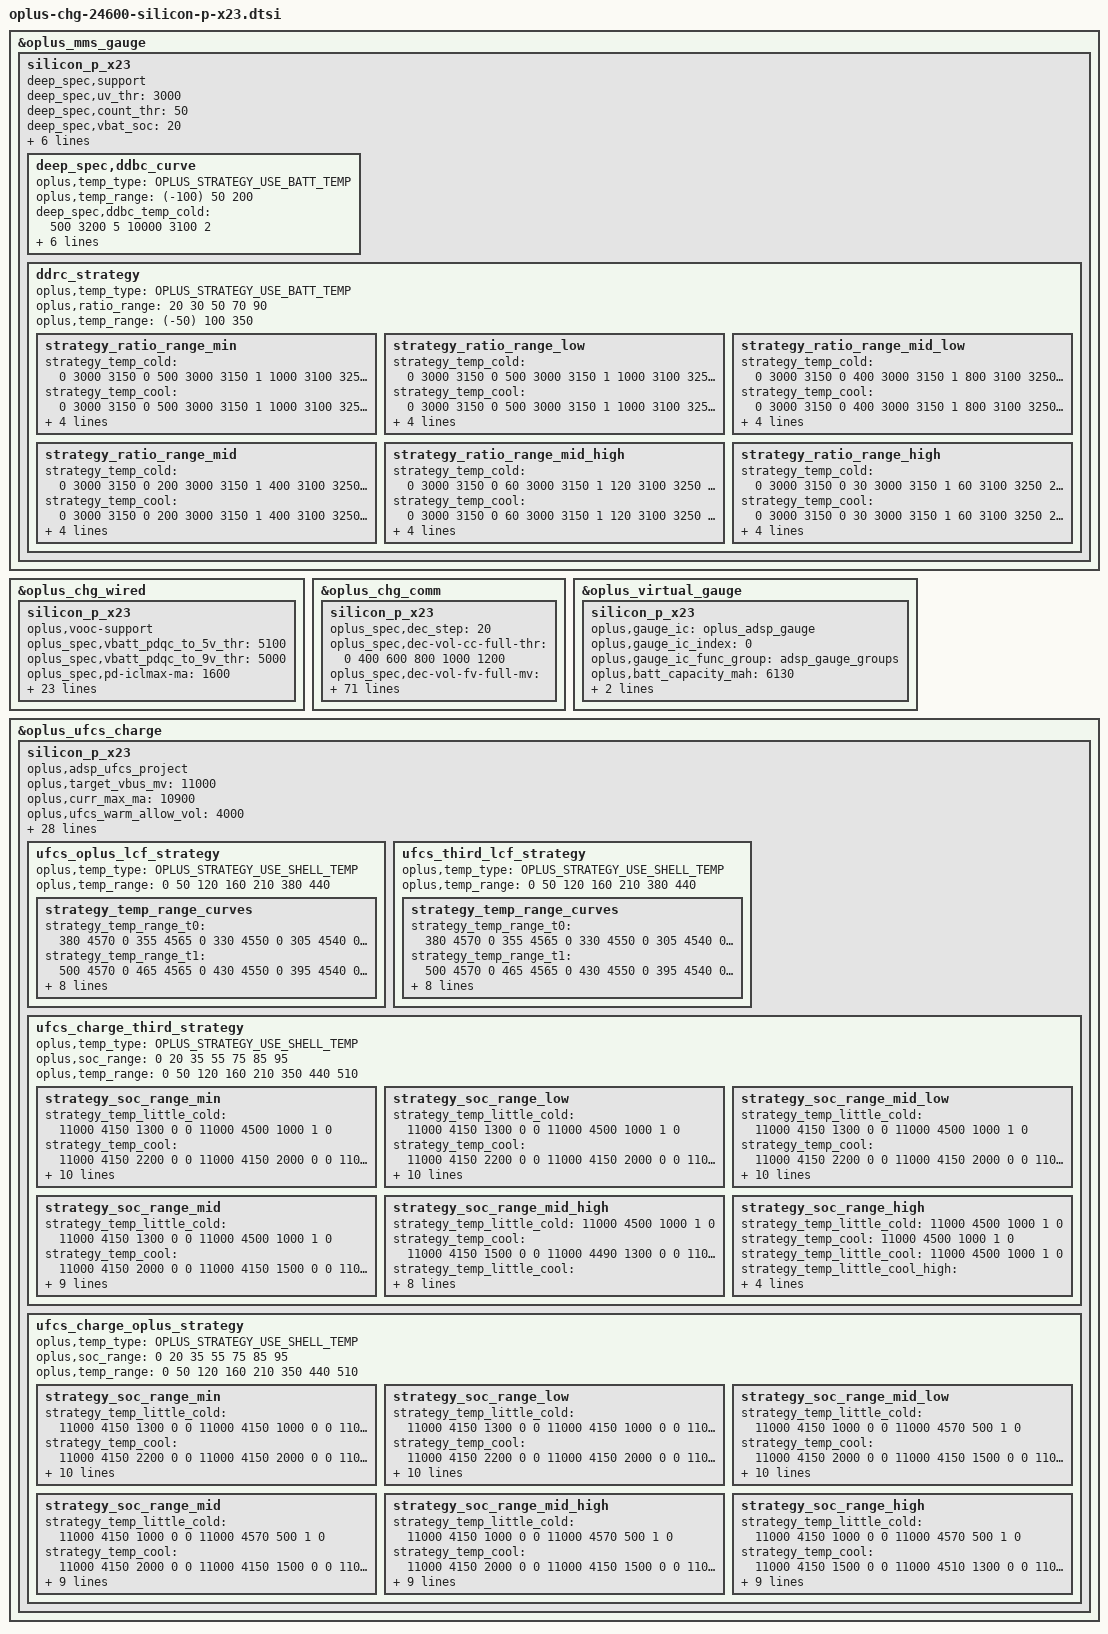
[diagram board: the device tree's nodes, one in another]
//ifdef OPLUS_FEATURE_CHG_BASIC

&oplus_mms_gauge {
	silicon_p_x23 {
		deep_spec,support;
		deep_spec,uv_thr = <3000>;
		deep_spec,count_thr = <50>;
		deep_spec,vbat_soc = <20>;
		deep_spec,count_step = <0 10 0
					350 12 1
					450 15 2
					530 20 3>;

		deep_spec,term_coeff = <3000 220 0
					3100 330 2
					3150 380 3
					3250 490 5
					3300 550 7
					3370 600 8
					3400 600 8>;
		deep_spec,ddrc_strategy_name = "ddrc_curve";
		deep_spec,volt_step = <20>;
		deep_spec,ddbc_curve {
			oplus,temp_type = <OPLUS_STRATEGY_USE_BATT_TEMP>;
			oplus,temp_range = <(-100) 50 200>;
			deep_spec,ddbc_temp_cold = <500 3200 5
						   10000 3100 2>;
			deep_spec,ddbc_temp_cool = <500 3300 5
						   10000 3200 2>;
			deep_spec,ddbc_temp_normal = <500 3400 5
						   10000 3350 2>;
			deep_spec,ddbc_temp_warm = <500 3400 5
						   10000 3350 2>;
		};
		ddrc_strategy {
			oplus,temp_type = <OPLUS_STRATEGY_USE_BATT_TEMP>;
			oplus,ratio_range = <20 30 50 70 90>;
			oplus,temp_range = <(-50) 100 350>;
			strategy_ratio_range_min {
				strategy_temp_cold =	<0 3000 3150 0
							500 3000 3150 1
							1000 3100 3250 2>;
				strategy_temp_cool =	<0 3000 3150 0
							500 3000 3150 1
							1000 3100 3250 2>;
				strategy_temp_normal =	<0 3000 3150 0
							500 3100 3250 1
							1000 3200 3300 2>;
				strategy_temp_warm =	<0 3000 3150 0
							500 3100 3250 1
							1000 3200 3300 2>;
			};
			strategy_ratio_range_low {
				strategy_temp_cold =	<0 3000 3150 0
							500 3000 3150 1
							1000 3100 3250 2>;
				strategy_temp_cool =	<0 3000 3150 0
							500 3000 3150 1
							1000 3100 3250 2>;
				strategy_temp_normal =	<0 3000 3150 0
							500 3100 3250 1
							1000 3200 3300 2>;
				strategy_temp_warm =	<0 3000 3150 0
							500 3100 3250 1
							1000 3200 3300 2>;
			};
			strategy_ratio_range_mid_low {
				strategy_temp_cold =	<0 3000 3150 0
							400 3000 3150 1
							800 3100 3250 2>;
				strategy_temp_cool =	<0 3000 3150 0
							400 3000 3150 1
							800 3100 3250 2>;
				strategy_temp_normal =	<0 3000 3150 0
							400 3100 3250 1
							800 3200 3300 2>;
				strategy_temp_warm =	<0 3000 3150 0
							400 3100 3250 1
							800 3200 3300 2>;
			};
			strategy_ratio_range_mid {
				strategy_temp_cold =	<0 3000 3150 0
							200 3000 3150 1
							400 3100 3250 2
							1000 3100 3250 3>;
				strategy_temp_cool =	<0 3000 3150 0
							200 3000 3150 1
							400 3100 3250 2
							1000 3200 3300 3>;
				strategy_temp_normal =	<0 3000 3150 0
							200 3100 3250 1
							400 3200 3300 2
							1000 3300 3370 3>;
				strategy_temp_warm =	<0 3000 3150 0
							200 3100 3250 1
							400 3200 3300 2
							1000 3300 3370 3>;
			};
			strategy_ratio_range_mid_high {
				strategy_temp_cold =	<0 3000 3150 0
							60 3000 3150 1
							120 3100 3250 2
							220 3100 3250 3
							1000 3200 3300 4>;
				strategy_temp_cool =	<0 3000 3150 0
							60 3000 3150 1
							120 3100 3250 2
							220 3200 3300 3
							1000 3200 3300 4>;
				strategy_temp_normal =	<0 3000 3150 0
							60 3100 3250 1
							120 3200 3300 2
							220 3300 3370 3
							1000 3350 3400 4>;
				strategy_temp_warm =	<0 3000 3150 0
							60 3100 3250 1
							120 3200 3300 2
							220 3300 3370 3
							800 3350 3400 4>;
			};
			strategy_ratio_range_high {
				strategy_temp_cold =	<0 3000 3150 0
							30 3000 3150 1
							60 3100 3250 2
							110 3200 3300 3
							160 3200 3300 4>;
				strategy_temp_cool =	<0 3000 3150 0
							30 3000 3150 1
							60 3100 3250 2
							110 3200 3300 3
							160 3200 3300 4>;
				strategy_temp_normal =	<0 3000 3150 0
							30 3100 3250 1
							60 3200 3300 2
							110 3300 3370 3
							160 3350 3400 4>;
				strategy_temp_warm =	<0 3000 3150 0
							30 3100 3250 1
							60 3200 3300 2
							110 3300 3370 3
							160 3350 3400 4>;
			};
		};
	};
};


&oplus_chg_wired {
	silicon_p_x23 {
		oplus,vooc-support;

		oplus_spec,vbatt_pdqc_to_5v_thr = <5100>;
		oplus_spec,vbatt_pdqc_to_9v_thr = <5000>;
		oplus_spec,pd-iclmax-ma = <1600>;
		oplus_spec,qc-iclmax-ma = <1600>;
		oplus_spec,non-standard-ibatmax-ma = <500>;
		oplus_spec,input-power-mw = <
			2500		/* OPLUS_WIRED_CHG_MODE_UNKNOWN */
			2500		/* OPLUS_WIRED_CHG_MODE_SDP */
			7500		/* OPLUS_WIRED_CHG_MODE_CDP */
			10000		/* OPLUS_WIRED_CHG_MODE_DCP */
			15000		/* OPLUS_WIRED_CHG_MODE_VOOC */
			14400		/* OPLUS_WIRED_CHG_MODE_QC */
			14400		/* OPLUS_WIRED_CHG_MODE_PD */
		>;
		oplus_spec,led_on-fccmax-ma = <0 788  1364 1760 1760 1760 1760 500 0>;
		oplus_spec,fccmax-ma-lv = <
			0 818 1100 1100 1100 1100 1100 1100  0	/* OPLUS_WIRED_CHG_MODE_UNKNOWN */
			0 300  300  300  300  300  300  300  0	/* OPLUS_WIRED_CHG_MODE_SDP */
			0 788  800  800  800  800  800  800  0	/* OPLUS_WIRED_CHG_MODE_CDP */
			0 788  1100 1100 1100 1100 1100 1100 0	/* OPLUS_WIRED_CHG_MODE_DCP */
			0 788  1314 1650 1650 1650 1650 1577 0	/* OPLUS_WIRED_CHG_MODE_VOOC */
			0 788  1314 1760 1760 1760 1760 1577 0	/* OPLUS_WIRED_CHG_MODE_QC */
			0 788  1314 1760 1760 1760 1760 1577 0	/* OPLUS_WIRED_CHG_MODE_PD */
		>;
		oplus_spec,fccmax-ma-hv = <
			0 263  526  1100 1100 1100 1100 1100  0	/* OPLUS_WIRED_CHG_MODE_UNKNOWN */
			0 263  300  300  300  300  300  300   0	/* OPLUS_WIRED_CHG_MODE_SDP */
			0 263  526  800  800  800  800  800   0	/* OPLUS_WIRED_CHG_MODE_CDP */
			0 263  526  1100 1100 1100 1100 1100  0	/* OPLUS_WIRED_CHG_MODE_DCP */
			0 263  526  1314 1314 1650 1650 1577  0	/* OPLUS_WIRED_CHG_MODE_VOOC */
			0 263  526  1314 1314 1760 1760 1577  0	/* OPLUS_WIRED_CHG_MODE_QC */
			0 263  526  1314 1314 1760 1760 1577  0	/* OPLUS_WIRED_CHG_MODE_PD */
		>;

		oplus_spec,cool_down_pdqc_vol_mv = <9000 9000 9000>;
		oplus_spec,cool_down_pdqc_curr_ma = <1200 1600 1600>;
		oplus_spec,cool_down_vooc_curr_ma = <1200 1500 2000 2500 3000 3000>;
		oplus_spec,cool_down_normal_curr_ma = <1200 1500 2000>;

		oplus_spec,vbus_ov_thr_mv = <11000 11000>;
		oplus_spec,vbus_uv_thr_mv = <4300 4300>;

		/* first data is strategy used temp type */
		oplus,vooc_strategy_name = "cgcl";
		oplus,vooc_strategy_data = <OPLUS_STRATEGY_USE_BATT_TEMP
					    0   350 3000 1 0
					    330 370 3000 2 0
					    350 440 2200 2 1>;
	};
};
&oplus_chg_comm {
	silicon_p_x23 {
		oplus_spec,dec_step = <20>;
		oplus_spec,dec-vol-cc-full-thr = <0 400 600 800 1000 1200>;
		oplus_spec,dec-vol-fv-full-mv = <0 20 20 40 40 40>;
		oplus_spec,batt-them-thr = <(-100) 0 50 120 160 350 450 530>;
		oplus_spec,iterm-ma = <156>;
		oplus_spec,fv-mv = <4500 4500 4500 4500 4500 4500 4485 4130 4130>;
		oplus_spec,sw-fv-mv = <4450 4450 4450 4450 4450 4450 4435 4080 4080>;
		oplus_spec,hw-fv-inc-mv = <0 18 18 18 18 18 18 18 0>;
		oplus_spec,sw-over-fv-mv = <4510 4510 4510 4510 4510 4510 4495 4140 4140>;
		oplus_spec,sw-over-fv-dec-mv = <8>;
		oplus_spec,non-standard-sw-fv-mv = <3930>;
		oplus_spec,non-standard-fv-mv = <3980>;
		oplus_spec,non-standard-hw-fv-inc-mv = <18>;
		oplus_spec,non-standard-sw-over-fv-mv = <3990>;
		oplus_spec,non-standard-vbatdet-mv = <3680>;
		oplus_spec,wired-vbatdet-mv = <0 4200 4300 4400 4400 4400 4385 4030 0>;
		oplus_spec,fcc-gear-thr-mv = <4180>;
		oplus_spec,fcc-gear-shake-mv = <400 400 400 300 300 180 180 180 180>;
		oplus_spec,vbatt-ov-thr-mv = <4600>;

		oplus_spec,full_pre_ffc_judge;
		oplus_spec,full-pre-ffc-mv = <4495>;
		oplus_spec,ffc-temp-thr = <120 200 350 440>;
		oplus_spec,wired-ffc-step-max = <2>;
		oplus_spec,wired-ffc-fv-mv = <4590 4590>;

		oplus_spec,wired-ffc-fv-cutoff-mv = <4545 4515 4500
						     4515 4505 4490>;

		oplus_spec,removed_bat_decidegc = <390>;

		oplus_spec,wired-ffc-fcc-ma = <550 550 550
					       350 350 350>;
		oplus_spec,wired-ffc-fcc-cutoff-ma = <400 400 400
						      200 200 200>;

		oplus_spec,drop_soc_2_temp_ladder = <(-50) 0 0 0 0 0 0 0 0 0>;
		oplus_spec,volt_diff_ladder_of_drop_soc_2 = <20 50 0 0 0 0 0 0 0 0>;
		oplus_spec,keep_soc_2_temp_ladder = <(-200) (-50) 0 0 0 0 0 0 0 0>;
		oplus_spec,volt_diff_ladder_of_keep_soc_2 = <10 20 30 0 0 0 0 0 0 0>;
		oplus_spec,back_rm_of_drop_soc_2 = <60>;
		oplus_spec,back_rm_of_drop_soc_1 = <60>;
		oplus_spec,load_current_of_drop_soc_2 = <500>;
		oplus_spec,load_current_of_drop_soc_1 = <1000>;
		oplus_spec,current_limit_of_drop_soc_2 = <350>;
		oplus_spec,volt_of_fast_drop_soc_1 = <3050>;
		oplus_spec,support_uisoc_low_battery_control;

		/* 2s battery */
		oplus_spec,wired-aging-ffc-version = <AGING_FFC_V1>;
		oplus_spec,wired-aging-ffc-offset-mv = <15 30
							10 20>;
		oplus_spec,wired-aging-ffc-cycle-thr = <500 1000>;

		oplus_spec,vbat_uv_thr_mv = <3000>;
		oplus_spec,vbat_charging_uv_thr_mv = <2900>;

		/*If use subboard NTC as battery temp, config it as 20, otherwise 0 */
		oplus_spec,tbatt_power_off_cali_temp = <0>;
		oplus,vooc_show_ui_soc_decimal;
		oplus_spec,poweroff_high_batt_temp = <720>;
		oplus_spec,poweroff_emergency_batt_temp = <770>;
		oplus,ui_soc_decimal_speedmin = <20>;

		oplus,gauge_stuck_jump_support;
		oplus,gauge_stuck_threshold = <15>;
		oplus,gauge_stuck_time = <50>;

		oplus,hidden_soc_switch;
		oplus,reserve_chg_soc = <3>;
		oplus,hidden_soc_percent = <20>;


		oplus,ui_soc_2_voltage_comp_mv = <30>;
		oplus,chg_shutdown_max_mv = <3000>;
	};
};

&oplus_virtual_gauge {
	silicon_p_x23 {
			oplus,gauge_ic = <&oplus_adsp_gauge>;
			oplus,gauge_ic_index = <0>;
			oplus,gauge_ic_func_group = <&adsp_gauge_groups>;
			oplus,batt_capacity_mah = <6130>;
			oplus,ic_type = <OPLUS_CHG_IC_VIRTUAL_GAUGE>;
			oplus,ic_index = <0>;
	};
};
&oplus_ufcs_charge {
	silicon_p_x23 {
		oplus,adsp_ufcs_project;

		oplus,target_vbus_mv = <11000>;
		oplus,curr_max_ma = <10900>;

		oplus,ufcs_warm_allow_vol = <4000>;
		oplus,ufcs_warm_allow_soc = <55>;
		oplus,ufcs_strategy_normal_current = <10900>;
		oplus,ufcs_over_high_or_low_current = <10900>;
		oplus,ufcs_timeout_third = <15582>;
		oplus,ufcs_timeout_oplus = <15582>;
		oplus,ufcs_ibat_over_third = <5400>;
		oplus,ufcs_ibat_over_oplus = <12300>;
		oplus,ufcs_ibus_over_oplus = <12300>;
		oplus,ufcs_full_cool_sw_vbat = <4570>;
		oplus,ufcs_full_normal_sw_vbat = <4570>;
		oplus,ufcs_full_normal_hw_vbat = <4580>;
		oplus,ufcs_full_ffc_vbat = <4540>;
		oplus,ufcs_full_warm_vbat = <4130>;
		oplus,ufcs_full_cool_sw_vbat_third = <4470>;
		oplus,ufcs_full_normal_sw_vbat_third= <4470>;
		oplus,ufcs_full_normal_hw_vbat_third = <4480>;
		oplus,ufcs_current_change_timeout = <100>;
		oplus,ufcs_strategy_batt_high_temp = <400 420 430 380 400 420>;
		oplus,ufcs_strategy_high_current = <7000 4000 3000 8000 6000 4000>;
		oplus,ufcs_little_cool_high_temp = <210>;
		oplus,curve_strategy_name = "pps_ufcs_curve_v2";
		oplus_spec,ufcs_high_soc = <95>;
		oplus,ufcs_charge_strategy_soc = <0 20 35 55 75 85 95>;
		oplus,ufcs_charge_strategy_temp = <0 50 120 160 350 440 510>;
		ufcs_oplus_lcf_strategy {
			oplus,temp_type = <OPLUS_STRATEGY_USE_SHELL_TEMP>;
			oplus,temp_range = <0 50 120 160 210 380 440>;

			strategy_temp_range_curves {
				strategy_temp_range_t0 =	<380 4570 0
								 355 4565 0
								 330 4550 0
								 305 4540 0
								 280 4530 1>;
				strategy_temp_range_t1 =	<500 4570 0
								 465 4565 0
								 430 4550 0
								 395 4540 0
								 360 4530 1>;
				strategy_temp_range_t2 =	<700 4570 0
								 650 4565 0
								 550 4550 0
								 450 4540 0
								 300 4530 1>;
				strategy_temp_range_t3 =	<1000 4570 0
								 950 4565 0
								 850 4550 0
								 750 4540 0
								 600 4530 1>;
				strategy_temp_range_t4 =	<1450 4570 0
								 1400 4565 0
								 1300 4550 0
								 1200 4540 0
								 1050 4530 1>;
				strategy_temp_range_t5 =	<1750 4570 0
								 1700 4565 0
								 1600 4550 0
								 1500 4540 0
								 1350 4530 1>;
			};
		};

		ufcs_third_lcf_strategy {
			oplus,temp_type = <OPLUS_STRATEGY_USE_SHELL_TEMP>;
			oplus,temp_range = <0 50 120 160 210 380 440>;

			strategy_temp_range_curves {
				strategy_temp_range_t0 =	<380 4570 0
								 355 4565 0
								 330 4550 0
								 305 4540 0
								 280 4530 1>;
				strategy_temp_range_t1 =	<500 4570 0
								 465 4565 0
								 430 4550 0
								 395 4540 0
								 360 4530 1>;
				strategy_temp_range_t2 =	<700 4570 0
								 650 4565 0
								 550 4550 0
								 450 4540 0
								 300 4530 1>;
				strategy_temp_range_t3 =	<1000 4570 0
								 950 4565 0
								 850 4550 0
								 750 4540 0
								 600 4530 1>;
				strategy_temp_range_t4 =	<1450 4570 0
								 1400 4565 0
								 1300 4550 0
								 1200 4540 0
								 1050 4530 1>;
				strategy_temp_range_t5 =	<1750 4570 0
								 1700 4565 0
								 1600 4550 0
								 1500 4540 0
								 1350 4530 1>;
			};
		};

		ufcs_charge_third_strategy {
			oplus,temp_type = <OPLUS_STRATEGY_USE_SHELL_TEMP>;
			oplus,soc_range = <0 20 35 55 75 85 95>;
			oplus,temp_range = <0 50 120 160 210 350 440 510>;

			strategy_soc_range_min {
				strategy_temp_little_cold =	<11000 4150 1300 0 0
								11000 4500 1000 1 0>;
				strategy_temp_cool =		<11000 4150 2200 0 0
								11000 4150 2000 0 0
								11000 4150 1500 0 0
								11000 4490 1300 0 0
								11000 4500 1000 1 0>;
				strategy_temp_little_cool =	<11000 4150 2800 0 0
								11000 4150 2500 0 0
								11000 4330 2200 0 0
								11000 4330 2000 0 0
								11000 4330 1500 0 0
								11000 4490 1300 0 0
								11000 4500 1000 1 0>;
				strategy_temp_little_cool_high = <11000 4330 4000 0 0
								11000 4330 3500 0 0
								11000 4490 3300 0 0
								11000 4490 3000 0 0
								11000 4490 2800 0 0
								11000 4490 2500 0 0
								11000 4490 2000 0 0
								11000 4490 1500 0 0
								11000 4500 1000 1 0>;
				strategy_temp_normal_low =	<11000 4490 4000 0 0
								11000 4490 3500 0 0
								11000 4490 3000 0 0
								11000 4490 2500 0 0
								11000 4490 2000 0 0
								11000 4490 1500 0 0
								11000 4500 1000 1 0>;
				strategy_temp_normal_high =	<11000 4475 4000 0 0
								11000 4475 3500 0 0
								11000 4475 3000 0 0
								11000 4475 2500 0 0
								11000 4475 2000 0 0
								11000 4475 1500 0 0
								11000 4485 1000 1 0>;
				strategy_temp_warm =		<11000 4120 1600 0 0
								11000 4120 1500 0 0
								11000 4130 1000 1 0>;
			};
			strategy_soc_range_low {
				strategy_temp_little_cold =	<11000 4150 1300 0 0
								11000 4500 1000 1 0>;
				strategy_temp_cool =		<11000 4150 2200 0 0
								11000 4150 2000 0 0
								11000 4150 1500 0 0
								11000 4490 1300 0 0
								11000 4500 1000 1 0>;
				strategy_temp_little_cool =	<11000 4150 2800 0 0
								11000 4150 2500 0 0
								11000 4330 2200 0 0
								11000 4330 2000 0 0
								11000 4330 1500 0 0
								11000 4490 1300 0 0
								11000 4500 1000 1 0>;
				strategy_temp_little_cool_high = <11000 4330 4000 0 0
								11000 4330 3500 0 0
								11000 4490 3300 0 0
								11000 4490 3000 0 0
								11000 4490 2800 0 0
								11000 4490 2500 0 0
								11000 4490 2000 0 0
								11000 4490 1500 0 0
								11000 4500 1000 1 0>;
				strategy_temp_normal_low =	<11000 4490 4000 0 0
								11000 4490 3500 0 0
								11000 4490 3000 0 0
								11000 4490 2500 0 0
								11000 4490 2000 0 0
								11000 4490 1500 0 0
								11000 4500 1000 1 0>;
				strategy_temp_normal_high =	<11000 4475 4000 0 0
								11000 4475 3500 0 0
								11000 4475 3000 0 0
								11000 4475 2500 0 0
								11000 4475 2000 0 0
								11000 4475 1500 0 0
								11000 4485 1000 1 0>;
				strategy_temp_warm =		<11000 4120 1600 0 0
								11000 4120 1500 0 0
								11000 4130 1000 1 0>;
			};
			strategy_soc_range_mid_low {
				strategy_temp_little_cold =	<11000 4150 1300 0 0
								11000 4500 1000 1 0>;
				strategy_temp_cool =		<11000 4150 2200 0 0
								11000 4150 2000 0 0
								11000 4150 1500 0 0
								11000 4490 1300 0 0
								11000 4500 1000 1 0>;
				strategy_temp_little_cool =	<11000 4150 2800 0 0
								11000 4150 2500 0 0
								11000 4330 2200 0 0
								11000 4330 2000 0 0
								11000 4330 1500 0 0
								11000 4490 1300 0 0
								11000 4500 1000 1 0>;
				strategy_temp_little_cool_high = <11000 4330 4000 0 0
								11000 4330 3500 0 0
								11000 4490 3300 0 0
								11000 4490 3000 0 0
								11000 4490 2800 0 0
								11000 4490 2500 0 0
								11000 4490 2000 0 0
								11000 4490 1500 0 0
								11000 4500 1000 1 0>;
				strategy_temp_normal_low =	<11000 4490 4000 0 0
								11000 4490 3500 0 0
								11000 4490 3000 0 0
								11000 4490 2500 0 0
								11000 4490 2000 0 0
								11000 4490 1500 0 0
								11000 4500 1000 1 0>;
				strategy_temp_normal_high =	<11000 4475 4000 0 0
								11000 4475 3500 0 0
								11000 4475 3000 0 0
								11000 4475 2500 0 0
								11000 4475 2000 0 0
								11000 4475 1500 0 0
								11000 4485 1000 1 0>;
				strategy_temp_warm =		<11000 4120 1600 0 0
								11000 4120 1500 0 0
								11000 4130 1000 1 0>;
			};
			strategy_soc_range_mid {
				strategy_temp_little_cold =	<11000 4150 1300 0 0
								11000 4500 1000 1 0>;
				strategy_temp_cool =		<11000 4150 2000 0 0
								11000 4150 1500 0 0
								11000 4490 1300 0 0
								11000 4500 1000 1 0>;
				strategy_temp_little_cool =	<11000 4150 2800 0 0
								11000 4150 2500 0 0
								11000 4330 2200 0 0
								11000 4330 2000 0 0
								11000 4330 1500 0 0
								11000 4490 1300 0 0
								11000 4500 1000 1 0>;
				strategy_temp_little_cool_high = <11000 4490 3000 0 0
								11000 4490 2800 0 0
								11000 4490 2500 0 0
								11000 4490 2000 0 0
								11000 4490 1500 0 0
								11000 4500 1000 1 0>;
				strategy_temp_normal_low =	<11000 4490 3500 0 0
								11000 4490 3000 0 0
								11000 4490 2500 0 0
								11000 4490 2000 0 0
								11000 4490 1500 0 0
								11000 4500 1000 1 0>;
				strategy_temp_normal_high =	<11000 4475 4000 0 0
								11000 4475 3500 0 0
								11000 4475 3000 0 0
								11000 4475 2500 0 0
								11000 4475 2000 0 0
								11000 4475 1500 0 0
								11000 4485 1000 1 0>;
				strategy_temp_warm =		<11000 4130 1000 1 0>;
			};
			strategy_soc_range_mid_high {
				strategy_temp_little_cold =	<11000 4500 1000 1 0>;
				strategy_temp_cool =		<11000 4150 1500 0 0
								11000 4490 1300 0 0
								11000 4500 1000 1 0>;
				strategy_temp_little_cool =	<11000 4330 2000 0 0
								11000 4330 1500 0 0
								11000 4490 1300 0 0
								11000 4500 1000 1 0>;
				strategy_temp_little_cool_high = <11000 4490 2000 0 0
								11000 4490 1500 0 0
								11000 4500 1000 1 0>;
				strategy_temp_normal_low =	<11000 4490 2500 0 0
								11000 4490 2000 0 0
								11000 4490 1500 0 0
								11000 4500 1000 1 0>;
				strategy_temp_normal_high =	<11000 4475 2500 0 0
								11000 4475 2000 0 0
								11000 4475 1500 0 0
								11000 4485 1000 1 0>;
				strategy_temp_warm =		<11000 4130 1000 1 0>;
			};
			strategy_soc_range_high {
				strategy_temp_little_cold =	<11000 4500 1000 1 0>;
				strategy_temp_cool =		<11000 4500 1000 1 0>;
				strategy_temp_little_cool =	<11000 4500 1000 1 0>;
				strategy_temp_little_cool_high = <11000 4500 1000 1 0>;
				strategy_temp_normal_low =	<11000 4500 1000 1 0>;
				strategy_temp_normal_high =	<11000 4485 1000 1 0>;
				strategy_temp_warm =		<11000 4130 1000 1 0>;
			};
		};

		ufcs_charge_oplus_strategy {
			oplus,temp_type = <OPLUS_STRATEGY_USE_SHELL_TEMP>;
			oplus,soc_range = <0 20 35 55 75 85 95>;
			oplus,temp_range = <0 50 120 160 210 350 440 510>;

			strategy_soc_range_min {
				strategy_temp_little_cold =	<11000 4150 1300 0 0
								11000 4150 1000 0 0
								11000 4570 500 1 0>;
				strategy_temp_cool =		<11000 4150 2200 0 0
								11000 4150 2000 0 0
								11000 4150 1500 0 0
								11000 4510 1300 0 0
								11000 4510 1000 0 0
								11000 4560 700 0 0
								11000 4570 500 1 0>;
				strategy_temp_little_cool =	<11000 4150 2800 0 0
								11000 4150 2500 0 0
								11000 4330 2200 0 0
								11000 4330 2000 0 0
								11000 4330 1500 0 0
								11000 4560 1300 0 0
								11000 4560 1000 0 0
								11000 4570 800 1 0>;
				strategy_temp_little_cool_high = <11000 4200 5600 0 0
								11000 4200 5500 0 0
								11000 4200 5000 0 0
								11000 4200 4500 0 0
								11000 4330 4200 0 0
								11000 4330 4000 0 0
								11000 4330 3500 0 0
								11000 4510 3300 0 0
								11000 4510 3000 0 0
								11000 4560 2800 0 0
								11000 4560 2500 0 0
								11000 4560 2000 0 0
								11000 4560 1500 0 0
								11000 4570 1100 1 0>;
				strategy_temp_normal_low =	<11000 4150 10900 0 0
								11000 4150 9100 0 0
								11000 4150 9000 0 0
								11000 4230 8900 0 0
								11000 4230 8500 0 0
								11000 4230 8000 0 0
								11000 4330 7500 0 0
								11000 4330 7000 0 0
								11000 4330 6500 0 0
								11000 4330 6000 0 0
								11000 4430 5600 0 0
								11000 4430 5500 0 0
								11000 4430 5000 0 0
								11000 4430 4500 0 0
								11000 4560 4200 0 0
								11000 4560 4000 0 0
								11000 4560 3500 0 0
								11000 4560 3000 0 0
								11000 4560 2500 0 0
								11000 4560 2000 0 0
								11000 4570 1500 1 0>;
				strategy_temp_normal_high =	<11000 4150 10900 0 0
								11000 4150 9100 0 0
								11000 4150 9000 0 0
								11000 4230 8900 0 0
								11000 4230 8500 0 0
								11000 4230 8000 0 0
								11000 4330 7500 0 0
								11000 4330 7000 0 0
								11000 4330 6500 0 0
								11000 4330 6000 0 0
								11000 4430 5600 0 0
								11000 4430 5500 0 0
								11000 4430 5000 0 0
								11000 4430 4500 0 0
								11000 4560 4200 0 0
								11000 4560 4000 0 0
								11000 4560 3500 0 0
								11000 4560 3000 0 0
								11000 4560 2500 0 0
								11000 4560 2000 0 0
								11000 4570 1800 1 0>;
				strategy_temp_warm =		<11000 4120 1600 0 0
								11000 4120 1500 0 0
								11000 4120 1000 0 0
								11000 4130 500 1 0>;
			};
			strategy_soc_range_low {
				strategy_temp_little_cold =	<11000 4150 1300 0 0
								11000 4150 1000 0 0
								11000 4570 500 1 0>;
				strategy_temp_cool =		<11000 4150 2200 0 0
								11000 4150 2000 0 0
								11000 4150 1500 0 0
								11000 4510 1300 0 0
								11000 4510 1000 0 0
								11000 4560 700 0 0
								11000 4570 500 1 0>;
				strategy_temp_little_cool =	<11000 4150 2800 0 0
								11000 4150 2500 0 0
								11000 4330 2200 0 0
								11000 4330 2000 0 0
								11000 4330 1500 0 0
								11000 4560 1300 0 0
								11000 4560 1000 0 0
								11000 4570 800 1 0>;
				strategy_temp_little_cool_high = <11000 4200 5600 0 0
								11000 4200 5500 0 0
								11000 4200 5000 0 0
								11000 4200 4500 0 0
								11000 4330 4200 0 0
								11000 4330 4000 0 0
								11000 4330 3500 0 0
								11000 4510 3300 0 0
								11000 4510 3000 0 0
								11000 4560 2800 0 0
								11000 4560 2500 0 0
								11000 4560 2000 0 0
								11000 4560 1500 0 0
								11000 4570 1100 1 0>;
				strategy_temp_normal_low =	<11000 4150 10900 0 0
								11000 4150 9100 0 0
								11000 4150 9000 0 0
								11000 4230 8900 0 0
								11000 4230 8500 0 0
								11000 4230 8000 0 0
								11000 4330 7500 0 0
								11000 4330 7000 0 0
								11000 4330 6500 0 0
								11000 4330 6000 0 0
								11000 4430 5600 0 0
								11000 4430 5500 0 0
								11000 4430 5000 0 0
								11000 4430 4500 0 0
								11000 4560 4200 0 0
								11000 4560 4000 0 0
								11000 4560 3500 0 0
								11000 4560 3000 0 0
								11000 4560 2500 0 0
								11000 4560 2000 0 0
								11000 4570 1500 1 0>;
				strategy_temp_normal_high =	<11000 4150 10900 0 0
								11000 4150 9100 0 0
								11000 4150 9000 0 0
								11000 4230 8900 0 0
								11000 4230 8500 0 0
								11000 4230 8000 0 0
								11000 4330 7500 0 0
								11000 4330 7000 0 0
								11000 4330 6500 0 0
								11000 4330 6000 0 0
								11000 4430 5600 0 0
								11000 4430 5500 0 0
								11000 4430 5000 0 0
								11000 4430 4500 0 0
								11000 4560 4200 0 0
								11000 4560 4000 0 0
								11000 4560 3500 0 0
								11000 4560 3000 0 0
								11000 4560 2500 0 0
								11000 4560 2000 0 0
								11000 4570 1800 1 0>;
				strategy_temp_warm =		<11000 4120 1600 0 0
								11000 4120 1500 0 0
								11000 4120 1000 0 0
								11000 4130 500 1 0>;
			};
			strategy_soc_range_mid_low {
				strategy_temp_little_cold =	<11000 4150 1000 0 0
								11000 4570 500 1 0>;
				strategy_temp_cool =		<11000 4150 2000 0 0
								11000 4150 1500 0 0
								11000 4510 1300 0 0
								11000 4510 1000 0 0
								11000 4560 700 0 0
								11000 4570 500 1 0>;
				strategy_temp_little_cool =	<11000 4150 2800 0 0
								11000 4150 2500 0 0
								11000 4330 2200 0 0
								11000 4330 2000 0 0
								11000 4330 1500 0 0
								11000 4560 1300 0 0
								11000 4560 1000 0 0
								11000 4570 800 1 0>;
				strategy_temp_little_cool_high = <11000 4200 5600 0 0
								11000 4200 5500 0 0
								11000 4200 5000 0 0
								11000 4200 4500 0 0
								11000 4330 4200 0 0
								11000 4330 4000 0 0
								11000 4330 3500 0 0
								11000 4510 3300 0 0
								11000 4510 3000 0 0
								11000 4560 2800 0 0
								11000 4560 2500 0 0
								11000 4560 2000 0 0
								11000 4560 1500 0 0
								11000 4570 1100 1 0>;
				strategy_temp_normal_low =	<11000 4150 10900 0 0
								11000 4150 9100 0 0
								11000 4150 9000 0 0
								11000 4230 8900 0 0
								11000 4230 8500 0 0
								11000 4230 8000 0 0
								11000 4330 7500 0 0
								11000 4330 7000 0 0
								11000 4330 6500 0 0
								11000 4330 6000 0 0
								11000 4430 5600 0 0
								11000 4430 5500 0 0
								11000 4430 5000 0 0
								11000 4430 4500 0 0
								11000 4560 4200 0 0
								11000 4560 4000 0 0
								11000 4560 3500 0 0
								11000 4560 3000 0 0
								11000 4560 2500 0 0
								11000 4560 2000 0 0
								11000 4570 1500 1 0>;
				strategy_temp_normal_high =	<11000 4150 10900 0 0
								11000 4150 9100 0 0
								11000 4150 9000 0 0
								11000 4230 8900 0 0
								11000 4230 8500 0 0
								11000 4230 8000 0 0
								11000 4330 7500 0 0
								11000 4330 7000 0 0
								11000 4330 6500 0 0
								11000 4330 6000 0 0
								11000 4430 5600 0 0
								11000 4430 5500 0 0
								11000 4430 5000 0 0
								11000 4430 4500 0 0
								11000 4560 4200 0 0
								11000 4560 4000 0 0
								11000 4560 3500 0 0
								11000 4560 3000 0 0
								11000 4560 2500 0 0
								11000 4560 2000 0 0
								11000 4570 1800 1 0>;
				strategy_temp_warm =		<11000 4120 1600 0 0
								11000 4120 1500 0 0
								11000 4120 1000 0 0
								11000 4130 500 1 0>;
			};
			strategy_soc_range_mid {
				strategy_temp_little_cold =	<11000 4150 1000 0 0
								11000 4570 500 1 0>;
				strategy_temp_cool =		<11000 4150 2000 0 0
								11000 4150 1500 0 0
								11000 4510 1300 0 0
								11000 4510 1000 0 0
								11000 4560 700 0 0
								11000 4570 500 1 0>;
				strategy_temp_little_cool =	<11000 4150 2800 0 0
								11000 4150 2500 0 0
								11000 4330 2200 0 0
								11000 4330 2000 0 0
								11000 4330 1500 0 0
								11000 4560 1300 0 0
								11000 4560 1000 0 0
								11000 4570 800 1 0>;
				strategy_temp_little_cool_high = <11000 4330 4000 0 0
								11000 4330 3500 0 0
								11000 4510 3300 0 0
								11000 4510 3000 0 0
								11000 4560 2800 0 0
								11000 4560 2500 0 0
								11000 4560 2000 0 0
								11000 4560 1500 0 0
								11000 4570 1100 1 0>;
				strategy_temp_normal_low =	<11000 4430 4500 0 0
								11000 4560 4200 0 0
								11000 4560 4000 0 0
								11000 4560 3500 0 0
								11000 4560 3000 0 0
								11000 4560 2500 0 0
								11000 4560 2000 0 0
								11000 4570 1500 1 0>;
				strategy_temp_normal_high =	<11000 4430 5000 0 0
								11000 4430 4500 0 0
								11000 4560 4200 0 0
								11000 4560 4000 0 0
								11000 4560 3500 0 0
								11000 4560 3000 0 0
								11000 4560 2500 0 0
								11000 4560 2000 0 0
								11000 4570 1800 1 0>;
				strategy_temp_warm =		<11000 4130 700 1 0>;
			};
			strategy_soc_range_mid_high {
				strategy_temp_little_cold =	<11000 4150 1000 0 0
								11000 4570 500 1 0>;
				strategy_temp_cool =		<11000 4150 2000 0 0
								11000 4150 1500 0 0
								11000 4510 1300 0 0
								11000 4510 1000 0 0
								11000 4560 700 0 0
								11000 4570 500 1 0>;
				strategy_temp_little_cool =	<11000 4150 2800 0 0
								11000 4150 2500 0 0
								11000 4330 2200 0 0
								11000 4330 2000 0 0
								11000 4330 1500 0 0
								11000 4560 1300 0 0
								11000 4560 1000 0 0
								11000 4570 800 1 0>;
				strategy_temp_little_cool_high = <11000 4510 3000 0 0
								11000 4560 2800 0 0
								11000 4560 2500 0 0
								11000 4560 2000 0 0
								11000 4560 1500 0 0
								11000 4570 1100 1 0>;
				strategy_temp_normal_low =	<11000 4560 3500 0 0
								11000 4560 3000 0 0
								11000 4560 2500 0 0
								11000 4560 2000 0 0
								11000 4570 1500 1 0>;
				strategy_temp_normal_high =	<11000 4560 3500 0 0
								11000 4560 3000 0 0
								11000 4560 2500 0 0
								11000 4560 2000 0 0
								11000 4570 1800 1 0>;
				strategy_temp_warm =		<11000 4130 1000 1 0>;
			};
			strategy_soc_range_high {
				strategy_temp_little_cold =	<11000 4150 1000 0 0
								11000 4570 500 1 0>;
				strategy_temp_cool =		<11000 4150 1500 0 0
								11000 4510 1300 0 0
								11000 4510 1000 0 0
								11000 4560 700 0 0
								11000 4570 500 1 0>;
				strategy_temp_little_cool =	<11000 4330 1500 0 0
								11000 4560 1300 0 0
								11000 4560 1000 0 0
								11000 4570 800 1 0>;
				strategy_temp_little_cool_high = <11000 4560 1500 0 0
								11000 4570 1100 1 0>;
				strategy_temp_normal_low =	<11000 4560 2000 0 0
								11000 4570 1500 1 0>;
				strategy_temp_normal_high =	<11000 4560 2000 0 0
								11000 4570 1800 1 0>;
				strategy_temp_warm =		<11000 4130 1000 1 0>;
			};
		};
	};
};

//#endif
